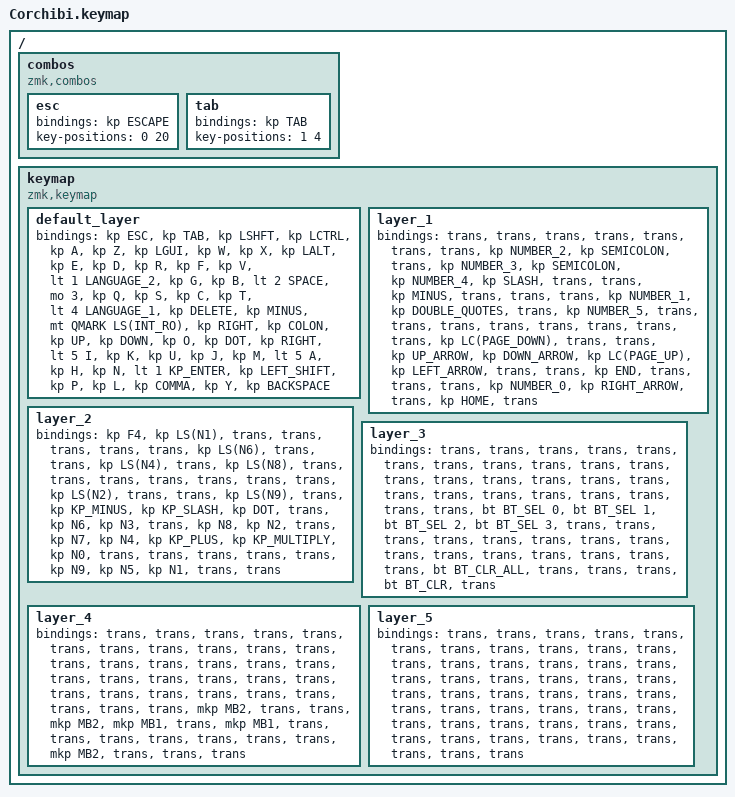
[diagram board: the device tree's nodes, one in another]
#include <dt-bindings/zmk/mouse.h>
#include <behaviors.dtsi>
#include <dt-bindings/zmk/bt.h>
#include <dt-bindings/zmk/keys.h>
#include <dt-bindings/zmk/pointing.h>

/ {
    combos {
        compatible = "zmk,combos";

        esc {
            bindings = <&kp ESCAPE>;
            key-positions = <0 20>;
        };

        tab {
            bindings = <&kp TAB>;
            key-positions = <1 4>;
        };
    };

    keymap {
        compatible = "zmk,keymap";

        default_layer {
            bindings = <
&kp ESC  &kp TAB  &kp LSHFT  &kp LCTRL  &kp A  &kp Z  &kp LGUI  &kp W  &kp X  &kp LALT  &kp E  &kp D  &kp R  &kp F  &kp V  &lt 1 LANGUAGE_2  &kp G  &kp B  &lt 2 SPACE  &mo 3  &kp Q  &kp S  &kp C  &kp T  &lt 4 LANGUAGE_1  &kp DELETE  &kp MINUS  &mt QMARK LS(INT_RO)  &kp RIGHT  &kp COLON  &kp UP  &kp DOWN  &kp O  &kp DOT  &kp RIGHT  &lt 5 I  &kp K  &kp U  &kp J  &kp M  &lt 5 A  &kp H  &kp N  &lt 1 KP_ENTER  &kp LEFT_SHIFT  &kp P  &kp L  &kp COMMA  &kp Y  &kp BACKSPACE
            >;
        };

        layer_1 {
            bindings = <
&trans  &trans  &trans  &trans  &trans  &trans  &trans  &kp NUMBER_2  &kp SEMICOLON  &trans  &kp NUMBER_3  &kp SEMICOLON  &kp NUMBER_4  &kp SLASH  &trans  &trans  &kp MINUS  &trans  &trans  &trans  &kp NUMBER_1  &kp DOUBLE_QUOTES  &trans  &kp NUMBER_5  &trans  &trans  &trans  &trans  &trans  &trans  &trans  &trans  &kp LC(PAGE_DOWN)  &trans  &trans  &kp UP_ARROW  &kp DOWN_ARROW  &kp LC(PAGE_UP)  &kp LEFT_ARROW  &trans  &trans  &kp END  &trans  &trans  &trans  &kp NUMBER_0  &kp RIGHT_ARROW  &trans  &kp HOME  &trans
            >;
        };

        layer_2 {
            bindings = <
&kp F4  &kp LS(N1)  &trans  &trans  &trans  &trans  &trans  &kp LS(N6)  &trans  &trans  &kp LS(N4)  &trans  &kp LS(N8)  &trans  &trans  &trans  &trans  &trans  &trans  &trans  &kp LS(N2)  &trans  &trans  &kp LS(N9)  &trans  &kp KP_MINUS  &kp KP_SLASH  &kp DOT  &trans  &kp N6  &kp N3  &trans  &kp N8  &kp N2  &trans  &kp N7  &kp N4  &kp KP_PLUS  &kp KP_MULTIPLY  &kp N0  &trans  &trans  &trans  &trans  &trans  &kp N9  &kp N5  &kp N1  &trans  &trans
            >;
        };

        layer_3 {
            bindings = <
&trans  &trans  &trans  &trans  &trans  &trans  &trans  &trans  &trans  &trans  &trans  &trans  &trans  &trans  &trans  &trans  &trans  &trans  &trans  &trans  &trans  &trans  &trans  &trans  &trans  &bt BT_SEL 0  &bt BT_SEL 1  &bt BT_SEL 2  &bt BT_SEL 3  &trans  &trans  &trans  &trans  &trans  &trans  &trans  &trans  &trans  &trans  &trans  &trans  &trans  &trans  &trans  &bt BT_CLR_ALL  &trans  &trans  &trans  &bt BT_CLR  &trans
            >;
        };

        layer_4 {
            bindings = <
&trans  &trans  &trans  &trans  &trans  &trans  &trans  &trans  &trans  &trans  &trans  &trans  &trans  &trans  &trans  &trans  &trans  &trans  &trans  &trans  &trans  &trans  &trans  &trans  &trans  &trans  &trans  &trans  &trans  &trans  &trans  &trans  &mkp MB2  &trans  &trans  &mkp MB2  &mkp MB1  &trans  &mkp MB1  &trans  &trans  &trans  &trans  &trans  &trans  &trans  &mkp MB2  &trans  &trans  &trans
            >;
        };

        layer_5 {
            bindings = <
&trans  &trans  &trans  &trans  &trans  &trans  &trans  &trans  &trans  &trans  &trans  &trans  &trans  &trans  &trans  &trans  &trans  &trans  &trans  &trans  &trans  &trans  &trans  &trans  &trans  &trans  &trans  &trans  &trans  &trans  &trans  &trans  &trans  &trans  &trans  &trans  &trans  &trans  &trans  &trans  &trans  &trans  &trans  &trans  &trans  &trans  &trans  &trans  &trans  &trans
            >;
        };
    };
};
